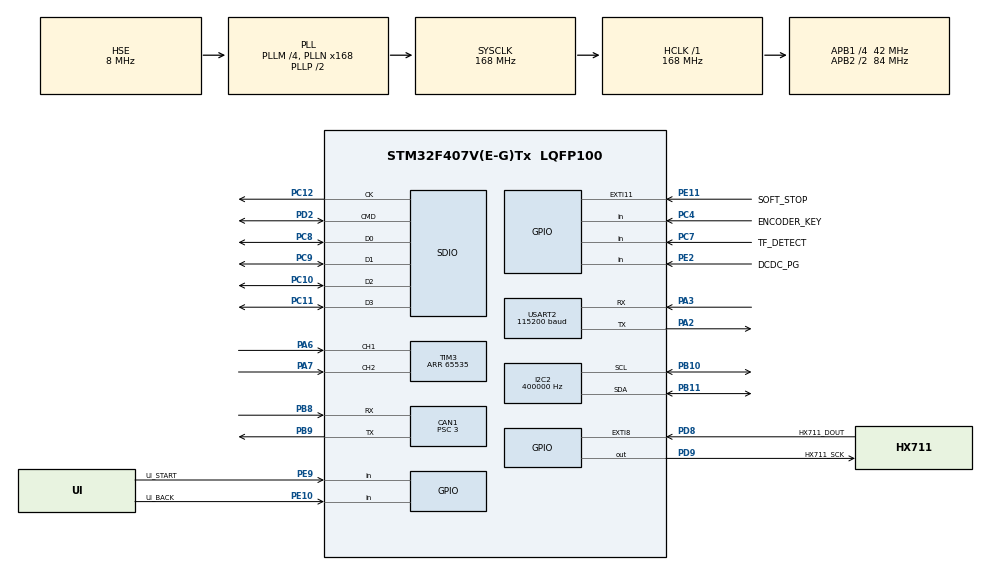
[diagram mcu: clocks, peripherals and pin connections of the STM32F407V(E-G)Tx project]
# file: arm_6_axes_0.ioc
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CAN1.ABOM=DISABLE
CAN1.BS1=CAN_BS1_11TQ
CAN1.BS2=CAN_BS2_2TQ
CAN1.CalculateBaudRate=1000000
CAN1.CalculateTimeBit=1000
CAN1.CalculateTimeQuantum=71.42857142857143
CAN1.NART=DISABLE
CAN1.Prescaler=3
CAN1.SJW=CAN_SJW_1TQ
Dma.Request0=SDIO_RX
Dma.Request1=SDIO_TX
Dma.SDIO_RX.0.Direction=DMA_PERIPH_TO_MEMORY
Dma.SDIO_RX.0.FIFOMode=DMA_FIFOMODE_ENABLE
Dma.SDIO_RX.0.FIFOThreshold=DMA_FIFO_THRESHOLD_FULL
Dma.SDIO_RX.0.Instance=DMA2_Stream3
Dma.SDIO_RX.0.MemBurst=DMA_MBURST_INC4
Dma.SDIO_RX.0.MemDataAlignment=DMA_MDATAALIGN_WORD
Dma.SDIO_RX.0.MemInc=DMA_MINC_ENABLE
Dma.SDIO_RX.0.Mode=DMA_PFCTRL
Dma.SDIO_RX.0.PeriphBurst=DMA_PBURST_INC4
Dma.SDIO_RX.0.PeriphDataAlignment=DMA_PDATAALIGN_WORD
Dma.SDIO_RX.0.PeriphInc=DMA_PINC_DISABLE
Dma.SDIO_RX.0.Priority=DMA_PRIORITY_LOW
Dma.SDIO_TX.1.Direction=DMA_MEMORY_TO_PERIPH
Dma.SDIO_TX.1.FIFOMode=DMA_FIFOMODE_ENABLE
Dma.SDIO_TX.1.FIFOThreshold=DMA_FIFO_THRESHOLD_FULL
Dma.SDIO_TX.1.Instance=DMA2_Stream6
Dma.SDIO_TX.1.MemBurst=DMA_MBURST_INC4
Dma.SDIO_TX.1.MemDataAlignment=DMA_MDATAALIGN_WORD
Dma.SDIO_TX.1.MemInc=DMA_MINC_ENABLE
Dma.SDIO_TX.1.Mode=DMA_PFCTRL
Dma.SDIO_TX.1.PeriphBurst=DMA_PBURST_INC4
Dma.SDIO_TX.1.PeriphDataAlignment=DMA_PDATAALIGN_WORD
Dma.SDIO_TX.1.PeriphInc=DMA_PINC_DISABLE
Dma.SDIO_TX.1.Priority=DMA_PRIORITY_LOW
FATFS.BSP.number=1
FATFS.USE_DMA_CODE_SD=1
FATFS._CODE_PAGE=437
FATFS._FS_REENTRANT=0
FATFS._MAX_LFN=31
FATFS._USE_LFN=1
FATFS._USE_STRFUNC=0
FATFS0.BSP.STBoard=false
FATFS0.BSP.api=Unknown
FATFS0.BSP.instance=PC7
FATFS0.BSP.ip=GPIO
FATFS0.BSP.mode=Input
FATFS0.BSP.name=Detect_SDIO
FATFS0.BSP.solution=PC7
FREERTOS.MEMORY_ALLOCATION=1
FREERTOS.Tasks01=defaultTask,0,128,StartDefaultTask,Default,NULL,Static,defaultTaskBuffer,defaultTaskControlBlock
FREERTOS.configTOTAL_HEAP_SIZE=15360
I2C2.ClockSpeed=400000
I2C2.I2C_Mode=I2C_Fast
Mcu.Family=STM32F4
Mcu.Name=STM32F407V(E-G)Tx
Mcu.Package=LQFP100
NVIC.CAN1_RX0_IRQn=true\:5\:0\:false\:false\:true\:true\:false\:true\:true
NVIC.CAN1_SCE_IRQn=true\:5\:0\:false\:false\:true\:true\:false\:true\:true
NVIC.DMA2_Stream3_IRQn=true\:5\:0\:false\:false\:true\:true\:false\:true\:true
NVIC.DMA2_Stream6_IRQn=true\:5\:0\:false\:false\:true\:true\:false\:true\:true
NVIC.EXTI15_10_IRQn=true\:5\:0\:false\:false\:true\:true\:false\:true\:true
NVIC.EXTI9_5_IRQn=true\:5\:0\:false\:false\:true\:true\:false\:true\:true
NVIC.PriorityGroup=NVIC_PRIORITYGROUP_4
NVIC.SDIO_IRQn=true\:5\:0\:false\:false\:true\:true\:false\:true\:true
NVIC.TIM1_UP_TIM10_IRQn=true\:15\:0\:false\:false\:true\:false\:false\:true\:true
NVIC.TimeBase=TIM1_UP_TIM10_IRQn
NVIC.TimeBaseIP=TIM1
NVIC.USART2_IRQn=true\:5\:0\:false\:false\:true\:true\:false\:true\:true
PA13.Mode=Serial_Wire
PA13.Signal=SYS_JTMS-SWDIO
PA14.Mode=Serial_Wire
PA14.Signal=SYS_JTCK-SWCLK
PA2.Mode=Asynchronous
PA2.Signal=USART2_TX
PA3.Mode=Asynchronous
PA3.Signal=USART2_RX
PA6.Signal=S_TIM3_CH1
PA7.Signal=S_TIM3_CH2
PB10.Mode=I2C
PB10.Signal=I2C2_SCL
PB11.Mode=I2C
PB11.Signal=I2C2_SDA
PB8.Mode=CAN_Activate
PB8.Signal=CAN1_RX
PB9.Mode=CAN_Activate
PB9.Signal=CAN1_TX
PC10.Mode=SD_4_bits_Wide_bus
PC10.Signal=SDIO_D2
PC11.Mode=SD_4_bits_Wide_bus
PC11.Signal=SDIO_D3
PC12.Mode=SD_4_bits_Wide_bus
PC12.Signal=SDIO_CK
PC4.GPIO_Label=ENCODER_KEY
PC4.GPIO_PuPd=GPIO_PULLUP
PC4.Signal=GPIO_Input
PC7.GPIO_Label=TF_DETECT
PC7.GPIO_PuPd=GPIO_PULLUP
PC7.Signal=GPIO_Input
PC8.Mode=SD_4_bits_Wide_bus
PC8.Signal=SDIO_D0
PC9.Mode=SD_4_bits_Wide_bus
PC9.Signal=SDIO_D1
PD2.Mode=SD_4_bits_Wide_bus
PD2.Signal=SDIO_CMD
PD8.GPIO_Label=HX711_DOUT
PD8.GPIO_ModeDefaultEXTI=GPIO_MODE_IT_FALLING
PD8.GPIO_PuPd=GPIO_PULLUP
PD8.Signal=GPXTI8
PD9.GPIO_Label=HX711_SCK
PD9.GPIO_PuPd=GPIO_NOPULL
PD9.Signal=GPIO_Output
PE10.GPIO_Label=UI_BACK
PE10.GPIO_PuPd=GPIO_PULLUP
PE10.Signal=GPIO_Input
PE11.GPIO_Label=SOFT_STOP
PE11.GPIO_ModeDefaultEXTI=GPIO_MODE_IT_FALLING
PE11.GPIO_PuPd=GPIO_PULLUP
PE11.Signal=GPXTI11
PE2.GPIO_Label=DCDC_PG
PE2.GPIO_PuPd=GPIO_NOPULL
PE2.Signal=GPIO_Input
PE9.GPIO_Label=UI_START
PE9.GPIO_PuPd=GPIO_PULLUP
PE9.Signal=GPIO_Input
PH0-OSC_IN.Mode=HSE-External-Oscillator
PH0-OSC_IN.Signal=RCC_OSC_IN
PH1-OSC_OUT.Mode=HSE-External-Oscillator
PH1-OSC_OUT.Signal=RCC_OSC_OUT
ProjectManager.HeapSize=0x0
ProjectManager.StackSize=0x1000
ProjectManager.TargetToolchain=Makefile
RCC.48MHZClocksFreq_Value=48000000
RCC.AHBFreq_Value=168000000
RCC.APB1CLKDivider=RCC_HCLK_DIV4
RCC.APB1Freq_Value=42000000
RCC.APB1TimFreq_Value=84000000
RCC.APB2CLKDivider=RCC_HCLK_DIV2
RCC.APB2Freq_Value=84000000
RCC.APB2TimFreq_Value=168000000
RCC.CortexFreq_Value=168000000
RCC.HCLKFreq_Value=168000000
RCC.HSE_VALUE=8000000
RCC.HSI_VALUE=16000000
RCC.LSE_VALUE=32768
RCC.PLLM=4
RCC.PLLN=168
RCC.PLLQ=7
RCC.PLLSourceVirtual=RCC_PLLSOURCE_HSE
RCC.RCC_RTC_Clock_Source_FROM_HSE=RCC_RTCCLKSOURCE_HSE_DIV8
RCC.SYSCLKFreq_VALUE=168000000
RCC.SYSCLKSource=RCC_SYSCLKSOURCE_PLLCLK
RCC.VCOOutputFreq_Value=336000000
SDIO.ClockDiv=4
SH.S_TIM3_CH1.0=TIM3_CH1,Encoder_Interface
SH.S_TIM3_CH2.0=TIM3_CH2,Encoder_Interface
TIM3.EncoderMode=TIM_ENCODERMODE_TI12
TIM3.Period=65535
USART2.BaudRate=115200
USART2.VirtualMode=VM_ASYNC
VP_FATFS_VS_SDIO.Mode=SDIO
VP_FREERTOS_VS_CMSIS_V1.Mode=CMSIS_V1
VP_SYS_VS_tim1.Mode=TIM1
board=custom

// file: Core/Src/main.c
/* USER CODE BEGIN Header */
/**
  ******************************************************************************
  * @file           : main.c
  * @brief          : Main program body
  ******************************************************************************
  * @attention
  *
  * Copyright (c) 2026 STMicroelectronics.
  * All rights reserved.
  *
  * This software is licensed under terms that can be found in the LICENSE file
  * in the root directory of this software component.
  * If no LICENSE file comes with this software, it is provided AS-IS.
  *
  ******************************************************************************
  */
/* USER CODE END Header */
#include "main.h"
#include "cmsis_os.h"
#include "can.h"
#include "dma.h"
#include "fatfs.h"
#include "i2c.h"
#include "sdio.h"
#include "tim.h"
#include "usart.h"
#include "gpio.h"

/* USER CODE BEGIN Includes */
#include "app_main.h"
#include "board_config.h"
/* USER CODE END Includes */

void SystemClock_Config(void);
void MX_FREERTOS_Init(void);

int main(void)
{

  /* MCU Configuration--------------------------------------------------------*/

  /* Reset of all peripherals, Initializes the Flash interface and the Systick. */
  HAL_Init();

  /* Configure the system clock */
  SystemClock_Config();

  /* Initialize all configured peripherals */
  MX_GPIO_Init();
  MX_DMA_Init();
  MX_SDIO_SD_Init();
  MX_I2C2_Init();
  MX_USART2_UART_Init();
  /* StorageTask owns FatFs initialization. */
  MX_CAN1_Init();
  MX_TIM3_Init();
  /* USER CODE BEGIN 2 */
  App_Init();
  /* USER CODE END 2 */

  /* Call init function for freertos objects (in cmsis_os2.c) */
  MX_FREERTOS_Init();

  /* Start scheduler */
  osKernelStart();

  /* We should never get here as control is now taken by the scheduler */

  /* Infinite loop */
  /* USER CODE BEGIN WHILE */
  App_Fatal(APP_FATAL_RTOS_OBJECT);
  while (1)
  {
  /* USER CODE END WHILE */

  }
}

void SystemClock_Config(void)
{
  RCC_OscInitTypeDef RCC_OscInitStruct = {0};
  RCC_ClkInitTypeDef RCC_ClkInitStruct = {0};

  /** Configure the main internal regulator output voltage
  */
  __HAL_RCC_PWR_CLK_ENABLE();
  __HAL_PWR_VOLTAGESCALING_CONFIG(PWR_REGULATOR_VOLTAGE_SCALE1);

  /** Initializes the RCC Oscillators according to the specified parameters
  * in the RCC_OscInitTypeDef structure.
  */
  RCC_OscInitStruct.OscillatorType = RCC_OSCILLATORTYPE_HSE;
  RCC_OscInitStruct.HSEState = RCC_HSE_ON;
  RCC_OscInitStruct.PLL.PLLState = RCC_PLL_ON;
  RCC_OscInitStruct.PLL.PLLSource = RCC_PLLSOURCE_HSE;
  RCC_OscInitStruct.PLL.PLLM = 4;
  RCC_OscInitStruct.PLL.PLLN = 168;
  RCC_OscInitStruct.PLL.PLLP = RCC_PLLP_DIV2;
  RCC_OscInitStruct.PLL.PLLQ = 7;
  if (HAL_RCC_OscConfig(&RCC_OscInitStruct) != HAL_OK)
  {
    Error_Handler();
  }

  /** Initializes the CPU, AHB and APB buses clocks
  */
  RCC_ClkInitStruct.ClockType = RCC_CLOCKTYPE_HCLK|RCC_CLOCKTYPE_SYSCLK
                              |RCC_CLOCKTYPE_PCLK1|RCC_CLOCKTYPE_PCLK2;
  RCC_ClkInitStruct.SYSCLKSource = RCC_SYSCLKSOURCE_PLLCLK;
  RCC_ClkInitStruct.AHBCLKDivider = RCC_SYSCLK_DIV1;
  RCC_ClkInitStruct.APB1CLKDivider = RCC_HCLK_DIV4;
  RCC_ClkInitStruct.APB2CLKDivider = RCC_HCLK_DIV2;

  if (HAL_RCC_ClockConfig(&RCC_ClkInitStruct, FLASH_LATENCY_5) != HAL_OK)
  {
    Error_Handler();
  }
}

void HAL_TIM_PeriodElapsedCallback(TIM_HandleTypeDef *htim)
{
  if (htim != NULL && htim->Instance == BOARD_HAL_TICK_INSTANCE)
  {
    HAL_IncTick();
  }
}

void Error_Handler(void)
{
  /* USER CODE BEGIN Error_Handler_Debug */
  App_Fatal(APP_FATAL_HAL);
  /* USER CODE END Error_Handler_Debug */
}

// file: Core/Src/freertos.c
/* USER CODE BEGIN Header */
/**
  ******************************************************************************
  * File Name          : freertos.c
  * Description        : Code for freertos applications
  ******************************************************************************
  * @attention
  *
  * Copyright (c) 2026 STMicroelectronics.
  * All rights reserved.
  *
  * This software is licensed under terms that can be found in the LICENSE file
  * in the root directory of this software component.
  * If no LICENSE file comes with this software, it is provided AS-IS.
  *
  ******************************************************************************
  */
/* USER CODE END Header */
#include "FreeRTOS.h"
#include "task.h"
#include "app_main.h"
static StaticTask_t idle_tcb;
static StackType_t idle_stack[configMINIMAL_STACK_SIZE];
void MX_FREERTOS_Init(void) { App_CreateTasks(); }
void vApplicationGetIdleTaskMemory(StaticTask_t **tcb, StackType_t **stack, uint32_t *size)
{ *tcb=&idle_tcb; *stack=idle_stack; *size=configMINIMAL_STACK_SIZE; }
